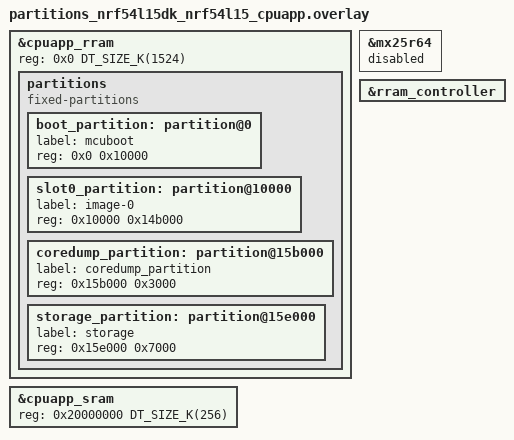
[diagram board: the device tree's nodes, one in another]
/*
 * Copyright (c) 2025 Nordic Semiconductor ASA
 *
 * SPDX-License-Identifier: LicenseRef-Nordic-5-Clause
 */

/delete-node/ &boot_partition;
/delete-node/ &slot0_partition;
/delete-node/ &slot0_ns_partition;
/delete-node/ &slot1_partition;
/delete-node/ &slot1_ns_partition;
/delete-node/ &storage_partition;

&cpuapp_rram {
	reg = < 0x0 DT_SIZE_K(1524) >;
	partitions {
		compatible = "fixed-partitions";
		#address-cells = <0x1>;
		#size-cells = <0x1>;
		boot_partition: partition@0 {
			label = "mcuboot";
			reg = <0x0 0x10000>;
		};
		slot0_partition: partition@10000 {
			label = "image-0";
			reg = <0x10000 0x14b000>;
		};
		coredump_partition: partition@15b000 {
			label = "coredump_partition";
			reg = <0x15b000 0x3000>;
		};
		storage_partition: partition@15e000 {
			label = "storage";
			reg = <0x15e000 0x7000>;
		};
	};
};

&mx25r64 {
	status = "disabled";
};

/* restore full SRAM space - by default some parts are dedicated to FLRP */
&cpuapp_sram {
	reg = <0x20000000 DT_SIZE_K(256)>;
	ranges = <0x0 0x20000000  0x40000>;
};

&rram_controller {
	/delete-node/ cpuflpr_sram;
	/delete-node/ cpuflpr_rram;
};
